# STM32F446xx register map
File version: 1.0
Registers are 32-bit, read-write, reset 0x0 unless marked. A register's access mark holds for its fields unless they carry their own. Offsets are from the block's base; [hi:lo] are bit positions; lines under a group give offsets from that group; {n}, {i} and the like mark numbered series.

## ADC123_COMMON
Base 0x40012300
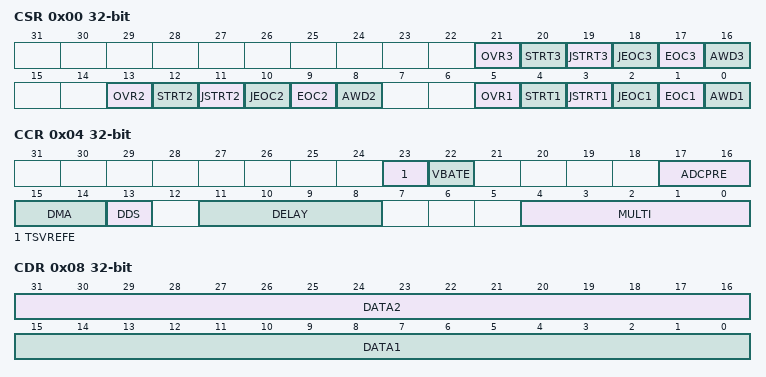
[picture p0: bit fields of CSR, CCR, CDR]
0x00 CSR — ADC Common status register
  [21] OVR3 — ADC3 DMA overrun flag
  [20] STRT3 — ADC3 Regular channel Start flag
  [19] JSTRT3 — ADC3 Injected channel Start flag
  [18] JEOC3 — ADC3 Injected channel end of conversion
  [17] EOC3 — ADC3 End of conversion
  [16] AWD3 — ADC3 Analog watchdog flag
  [13] OVR2 — ADC2 DMA overrun flag
  [12] STRT2 — ADC2 Regular channel Start flag
  [11] JSTRT2 — ADC2 Injected channel Start flag
  [10] JEOC2 — ADC2 Injected channel end of conversion
  [9] EOC2 — ADC2 End of conversion
  [8] AWD2 — ADC2 Analog watchdog flag
  [5] OVR1 — ADC1 DMA overrun flag
  [4] STRT1 — ADC1 Regular channel Start flag
  [3] JSTRT1 — ADC1 Injected channel Start flag
  [2] JEOC1 — ADC1 Injected channel end of conversion
  [1] EOC1 — ADC1 End of conversion
  [0] AWD1 — ADC1 Analog watchdog flag
0x04 CCR — ADC common control register
  [23] TSVREFE — Temperature Sensor and VREFINT Enable
  [22] VBATE — VBAT Enable
  [17:16] ADCPRE — ADCPRE[1:0] bits (ADC prescaler)
    0=DIV2 (ADC synchronous clock derived from AHB clock with prescaler division by 2); 1=DIV4 (ADC synchronous clock derived from AHB clock with prescaler division by 4); 2=DIV6 (ADC synchronous clock derived from AHB clock with prescaler division by 6); 3=DIV8 (ADC synchronous clock derived from AHB clock with prescaler division by 8)
  [15:14] DMA — DMA[1:0] bits (Direct Memory Access mode for multimode)
  [13] DDS — DMA disable selection (Multi-ADC mode)
  [11:8] DELAY — DELAY[3:0] bits (Delay between 2 sampling phases)
    {v}=DELAY_{v+5}CYCLES (ADC multimode delay between two sampling phases: {v+5} ADC clock cycles) (v=0..15)
  [4:0] MULTI — MULTI[4:0] bits (Multi-ADC mode selection)
    0=INDEPENDENT (ADC dual mode disabled (ADC independent mode)); 6=DUAL_REG_SIMULT (ADC dual mode enabled: group regular simultaneous); 7=DUAL_REG_INTERL (ADC dual mode enabled: Combined group regular interleaved); 5=DUAL_INJ_SIMULT (ADC dual mode enabled: group injected simultaneous); 9=DUAL_INJ_ALTERN (ADC dual mode enabled: group injected alternate trigger. Works only with external triggers (not internal SW start)); 1=DUAL_REG_SIM_INJ_SIM (ADC dual mode enabled: Combined group regular simultaneous + group injected simultaneous); 2=DUAL_REG_SIM_INJ_ALT (ADC dual mode enabled: Combined group regular simultaneous + group injected alternate trigger); 3=DUAL_REG_INT_INJ_SIM (ADC dual mode enabled: Combined group regular interleaved + group injected simultaneous); 17=TRIPLE_REG_SIM_INJ_SIM (ADC triple mode enabled: Combined group regular simultaneous + group injected simultaneous); 18=TRIPLE_REG_SIM_INJ_ALT (ADC triple mode enabled: Combined group regular simultaneous + group injected alternate trigger); 21=TRIPLE_INJ_SIMULT (ADC triple mode enabled: group injected simultaneous); 22=TRIPLE_REG_SIMULT (ADC triple mode enabled: group regular simultaneous); 23=TRIPLE_REG_INTERL (ADC triple mode enabled: Combined group regular interleaved)
0x08 CDR — ADC common regular data register for dual AND triple modes
  [31:16] DATA2 — 2nd data of a pair of regular conversions
  [15:0] DATA1 — 1st data of a pair of regular conversions

## SYSCFG — System configuration controller
Base 0x40013800
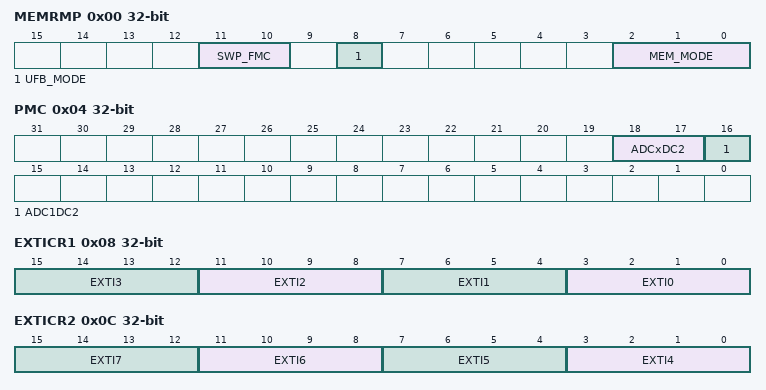
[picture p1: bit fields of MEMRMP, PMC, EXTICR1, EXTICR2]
0x00 MEMRMP — SYSCFG memory remap register
  [11:10] SWP_FMC — FMC memory mapping swap
  [8] UFB_MODE — User Flash Bank mode
    0=BANK1; 1=BANK2
  [2:0] MEM_MODE — SYSCFG_Memory Remap Config
    0=FLASH (Main Flash memory mapped at 0x00000000); 1=SYSTEMFLASH (System Flash memory mapped at 0x00000000); 3=SRAM (SRAM1 mapped at 0x00000000); 2=FMC (FMC(NOR/PSRAM 1 and 2) mapped at 0x00000000)
0x04 PMC — SYSCFG peripheral mode configuration register
  [18:17] ADCxDC2 — Refer to AN4073 on how to use this bit
  [16] ADC1DC2 — Refer to AN4073 on how to use this bit
0x08 EXTICR1 — SYSCFG external interrupt configuration registers
  [4n+3:4n] EXTI{n} (n=0..3) — EXTI {n} configuration
0x0C EXTICR2 — SYSCFG external interrupt configuration registers
  [4n-13:4n-16] EXTI{n} (n=4..7) — EXTI {n} configuration
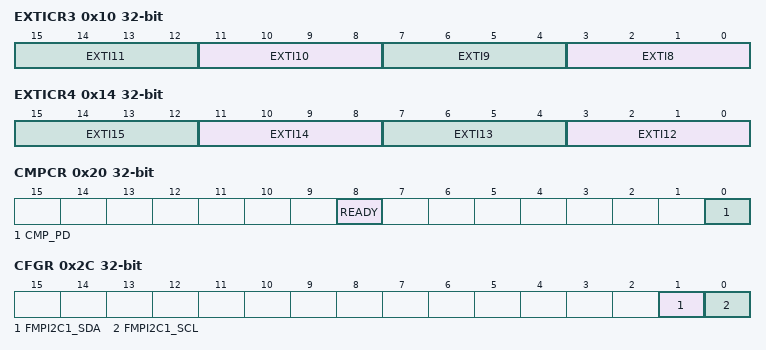
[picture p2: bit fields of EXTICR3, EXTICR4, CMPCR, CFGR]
0x10 EXTICR3 — SYSCFG external interrupt configuration registers
  [4n-29:4n-32] EXTI{n} (n=8..11) — EXTI {n} configuration
0x14 EXTICR4 — SYSCFG external interrupt configuration registers
  [4n-45:4n-48] EXTI{n} (n=12..15) — EXTI {n} configuration
0x20 CMPCR — SYSCFG Compensation cell control register
  [8] READY — Compensation cell power-down
  [0] CMP_PD — Compensation cell ready flag
0x2C CFGR — SYSCFG Configuration register
  [1] FMPI2C1_SDA — FM+ drive capability for FMPI2C1_SDA pin
  [0] FMPI2C1_SCL — FM+ drive capability for FMPI2C1_SCL pin
